VERSION ""

NS_ :

BS_:

BU_:

BO_ 3221225472 VECTOR__INDEPENDENT_SIG_MSG: 0 Vector__XXX
 SG_ Low_FlowRate : 0|8@1+ (1,0) [0|0] "" Vector__XXX
 SG_ NewSignal_0002 : 8|8@1+ (1,0) [0|0] "" Vector__XXX

BO_ 896 HEARTBEAT: 8 Vector__XXX
 SG_ State : 0|8@1+ (1,0) [0|0] "" Vector__XXX
 SG_ Counter : 8|8@1+ (1,0) [0|0] "" Vector__XXX

BO_ 897 ERROR: 8 Vector__XXX
 SG_ A : 0|8@1+ (1,0) [0|0] "" Vector__XXX

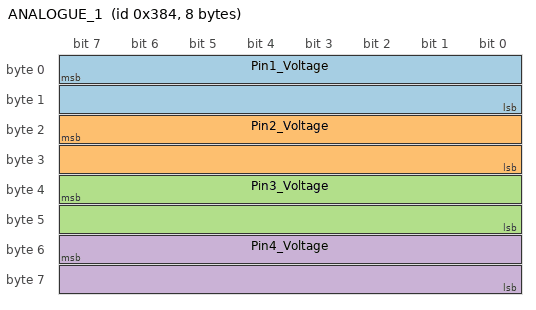
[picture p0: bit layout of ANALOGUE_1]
BO_ 900 ANALOGUE_1: 8 Vector__XXX
 SG_ Pin1_Voltage : 7|16@0+ (0.001,0) [0|0] "V" Vector__XXX
 SG_ Pin2_Voltage : 23|16@0+ (0.001,0) [0|0] "V" Vector__XXX
 SG_ Pin3_Voltage : 39|16@0+ (0.001,0) [0|0] "V" Vector__XXX
 SG_ Pin4_Voltage : 55|16@0+ (0.001,0) [0|0] "V" Vector__XXX

BO_ 901 ANALOGUE_2: 8 Vector__XXX
 SG_ LSP_RAD_INLET_TEMP : 7|16@0+ (0.01,0) [0|0] "C" Vector__XXX
 SG_ LSP_RAD_OUTLET_TEMP : 23|16@0+ (0.01,0) [0|0] "C" Vector__XXX
